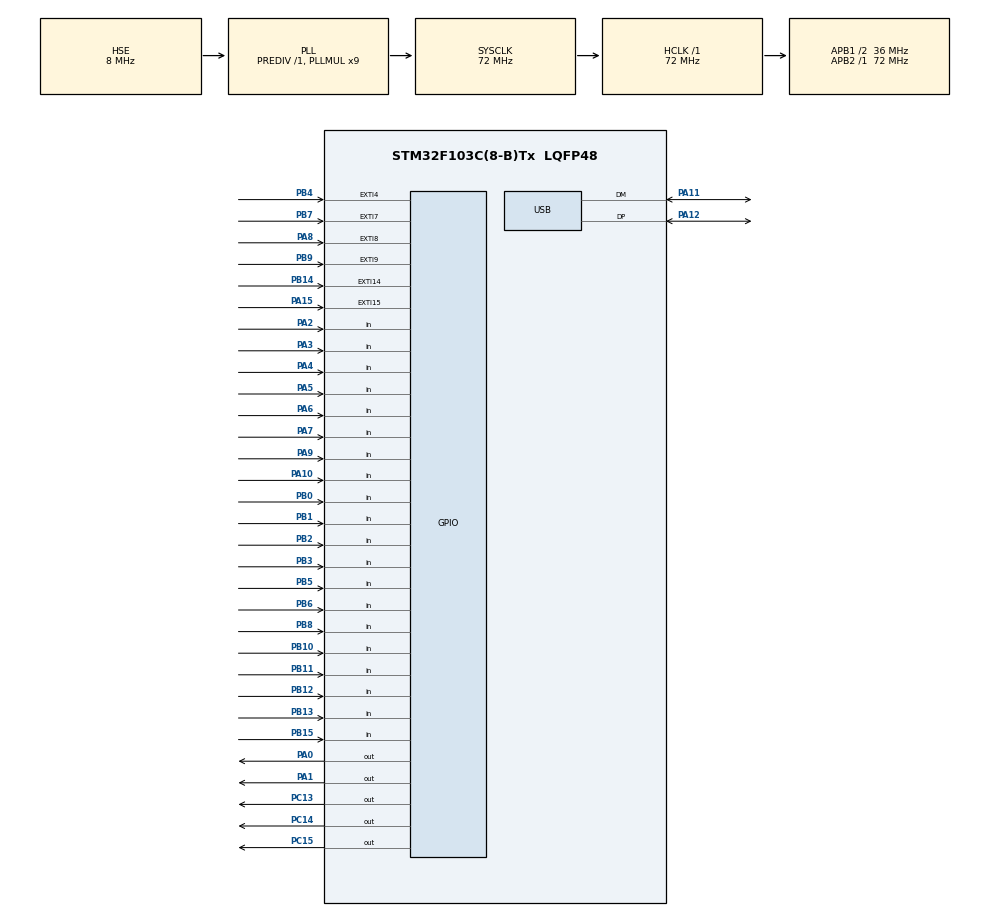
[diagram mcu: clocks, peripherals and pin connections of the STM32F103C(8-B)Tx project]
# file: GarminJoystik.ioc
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Mcu.Family=STM32F1
Mcu.Name=STM32F103C(8-B)Tx
Mcu.Package=LQFP48
NVIC.EXTI15_10_IRQn=true\:0\:0\:false\:false\:true\:true
NVIC.EXTI9_5_IRQn=true\:0\:0\:false\:false\:true\:true
NVIC.PriorityGroup=NVIC_PRIORITYGROUP_4
NVIC.USB_LP_CAN1_RX0_IRQn=true\:0\:0\:false\:false\:true\:true
PA0-WKUP.PinState=GPIO_PIN_SET
PA0-WKUP.Signal=GPIO_Output
PA1.PinState=GPIO_PIN_SET
PA1.Signal=GPIO_Output
PA10.GPIO_Mode=GPIO_MODE_INPUT
PA10.GPIO_PuPd=GPIO_PULLUP
PA10.Signal=GPIO_Input
PA11.Mode=Device
PA11.Signal=USB_DM
PA12.Mode=Device
PA12.Signal=USB_DP
PA13.Signal=SYS_JTMS-SWDIO
PA14.Signal=SYS_JTCK-SWCLK
PA15.GPIO_ModeDefaultEXTI=GPIO_MODE_IT_FALLING
PA15.GPIO_PuPd=GPIO_PULLUP
PA15.Signal=GPXTI15
PA2.GPIO_Mode=GPIO_MODE_INPUT
PA2.GPIO_PuPd=GPIO_PULLDOWN
PA2.Signal=GPIO_Input
PA3.GPIO_Mode=GPIO_MODE_INPUT
PA3.GPIO_PuPd=GPIO_PULLDOWN
PA3.Signal=GPIO_Input
PA4.GPIO_Mode=GPIO_MODE_INPUT
PA4.GPIO_PuPd=GPIO_PULLDOWN
PA4.Signal=GPIO_Input
PA5.GPIO_Mode=GPIO_MODE_INPUT
PA5.GPIO_PuPd=GPIO_PULLDOWN
PA5.Signal=GPIO_Input
PA6.GPIO_Mode=GPIO_MODE_INPUT
PA6.GPIO_PuPd=GPIO_PULLDOWN
PA6.Signal=GPIO_Input
PA7.GPIO_Mode=GPIO_MODE_INPUT
PA7.GPIO_PuPd=GPIO_PULLDOWN
PA7.Signal=GPIO_Input
PA8.GPIO_ModeDefaultEXTI=GPIO_MODE_IT_FALLING
PA8.GPIO_PuPd=GPIO_PULLUP
PA8.Signal=GPXTI8
PA9.GPIO_Mode=GPIO_MODE_INPUT
PA9.GPIO_PuPd=GPIO_PULLUP
PA9.Signal=GPIO_Input
PB0.GPIO_Mode=GPIO_MODE_INPUT
PB0.GPIO_PuPd=GPIO_PULLDOWN
PB0.Signal=GPIO_Input
PB1.GPIO_Mode=GPIO_MODE_INPUT
PB1.GPIO_PuPd=GPIO_PULLDOWN
PB1.Signal=GPIO_Input
PB10.GPIO_Mode=GPIO_MODE_INPUT
PB10.GPIO_PuPd=GPIO_PULLDOWN
PB10.Signal=GPIO_Input
PB11.GPIO_Mode=GPIO_MODE_INPUT
PB11.GPIO_PuPd=GPIO_PULLDOWN
PB11.Signal=GPIO_Input
PB12.GPIO_Mode=GPIO_MODE_INPUT
PB12.GPIO_PuPd=GPIO_PULLUP
PB12.Signal=GPIO_Input
PB13.GPIO_Mode=GPIO_MODE_INPUT
PB13.GPIO_PuPd=GPIO_PULLUP
PB13.Signal=GPIO_Input
PB14.GPIO_ModeDefaultEXTI=GPIO_MODE_IT_FALLING
PB14.GPIO_PuPd=GPIO_PULLUP
PB14.Signal=GPXTI14
PB15.GPIO_Mode=GPIO_MODE_INPUT
PB15.GPIO_PuPd=GPIO_PULLUP
PB15.Signal=GPIO_Input
PB2.GPIO_Mode=GPIO_MODE_INPUT
PB2.GPIO_PuPd=GPIO_PULLDOWN
PB2.Signal=GPIO_Input
PB3.GPIO_Mode=GPIO_MODE_INPUT
PB3.GPIO_PuPd=GPIO_PULLUP
PB3.Signal=GPIO_Input
PB4.GPIO_ModeDefaultEXTI=GPIO_MODE_IT_FALLING
PB4.GPIO_PuPd=GPIO_PULLUP
PB4.Signal=GPXTI4
PB5.GPIO_Mode=GPIO_MODE_INPUT
PB5.GPIO_PuPd=GPIO_PULLUP
PB5.Signal=GPIO_Input
PB6.GPIO_Mode=GPIO_MODE_INPUT
PB6.GPIO_PuPd=GPIO_PULLUP
PB6.Signal=GPIO_Input
PB7.GPIO_ModeDefaultEXTI=GPIO_MODE_IT_FALLING
PB7.GPIO_PuPd=GPIO_PULLUP
PB7.Signal=GPXTI7
PB8.GPIO_Mode=GPIO_MODE_INPUT
PB8.GPIO_PuPd=GPIO_PULLUP
PB8.Signal=GPIO_Input
PB9.GPIO_ModeDefaultEXTI=GPIO_MODE_IT_FALLING
PB9.GPIO_PuPd=GPIO_PULLUP
PB9.Signal=GPXTI9
PC13-TAMPER-RTC.PinState=GPIO_PIN_SET
PC13-TAMPER-RTC.Signal=GPIO_Output
PC14-OSC32_IN.PinState=GPIO_PIN_SET
PC14-OSC32_IN.Signal=GPIO_Output
PC15-OSC32_OUT.PinState=GPIO_PIN_SET
PC15-OSC32_OUT.Signal=GPIO_Output
PD0-OSC_IN.Mode=HSE-External-Oscillator
PD0-OSC_IN.Signal=RCC_OSC_IN
PD1-OSC_OUT.Mode=HSE-External-Oscillator
PD1-OSC_OUT.Signal=RCC_OSC_OUT
ProjectManager.HeapSize=0x200
ProjectManager.StackSize=0x400
ProjectManager.TargetToolchain=SW4STM32
RCC.AHBFreq_Value=72000000
RCC.APB1CLKDivider=RCC_HCLK_DIV2
RCC.APB1Freq_Value=36000000
RCC.APB1TimFreq_Value=72000000
RCC.APB2Freq_Value=72000000
RCC.APB2TimFreq_Value=72000000
RCC.HCLKFreq_Value=72000000
RCC.PLLMUL=RCC_PLL_MUL9
RCC.SYSCLKFreq_VALUE=72000000
RCC.SYSCLKSource=RCC_SYSCLKSOURCE_PLLCLK
RCC.USBFreq_Value=48000000
RCC.USBPrescaler=RCC_USBCLKSOURCE_PLL_DIV1_5
USB_DEVICE.CLASS_NAME_FS=CUSTOMHID
USB_DEVICE.MANUFACTURER_STRING=Iezious
USB_DEVICE.PID_CUSTOMHID_FS=53223 
USB_DEVICE.PRODUCT_STRING_CUSTOMHID_FS=GNS530 Joystick
USB_DEVICE.SERIALNUMBER_STRING_CUSTOMHID_FS=00000000011B
USB_DEVICE.VirtualMode=CustomHid
USB_DEVICE.VirtualModeFS=Custom_Hid_FS
VP_SYS_VS_ND.Mode=No_Debug
VP_USB_DEVICE_VS_USB_DEVICE_CUSTOM_HID_FS.Mode=CUSTOM_HID_FS
board=custom

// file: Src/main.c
/**
  ******************************************************************************
  * @file           : main.c
  * @brief          : Main program body
  ******************************************************************************
  * This notice applies to any and all portions of this file
  * that are not between comment pairs USER CODE BEGIN and
  * USER CODE END. Other portions of this file, whether
  * inserted by the user or by software development tools
  * are owned by their respective copyright owners.
  *
  * Copyright (c) 2018 STMicroelectronics International N.V.
  * All rights reserved.
  *
  * Redistribution and use in source and binary forms, with or without
  * modification, are permitted, provided that the following conditions are met:
  *
  * 1. Redistribution of source code must retain the above copyright notice,
  *    this list of conditions and the following disclaimer.
  * 2. Redistributions in binary form must reproduce the above copyright notice,
  *    this list of conditions and the following disclaimer in the documentation
  *    and/or other materials provided with the distribution.
  * 3. Neither the name of STMicroelectronics nor the names of other
  *    contributors to this software may be used to endorse or promote products
  *    derived from this software without specific written permission.
  * 4. This software, including modifications and/or derivative works of this
  *    software, must execute solely and exclusively on microcontroller or
  *    microprocessor devices manufactured by or for STMicroelectronics.
  * 5. Redistribution and use of this software other than as permitted under
  *    this license is void and will automatically terminate your rights under
  *    this license.
  *
  * THIS SOFTWARE IS PROVIDED BY STMICROELECTRONICS AND CONTRIBUTORS "AS IS"
  * AND ANY EXPRESS, IMPLIED OR STATUTORY WARRANTIES, INCLUDING, BUT NOT
  * LIMITED TO, THE IMPLIED WARRANTIES OF MERCHANTABILITY, FITNESS FOR A
  * PARTICULAR PURPOSE AND NON-INFRINGEMENT OF THIRD PARTY INTELLECTUAL PROPERTY
  * RIGHTS ARE DISCLAIMED TO THE FULLEST EXTENT PERMITTED BY LAW. IN NO EVENT
  * SHALL STMICROELECTRONICS OR CONTRIBUTORS BE LIABLE FOR ANY DIRECT, INDIRECT,
  * INCIDENTAL, SPECIAL, EXEMPLARY, OR CONSEQUENTIAL DAMAGES (INCLUDING, BUT NOT
  * LIMITED TO, PROCUREMENT OF SUBSTITUTE GOODS OR SERVICES; LOSS OF USE, DATA,
  * OR PROFITS; OR BUSINESS INTERRUPTION) HOWEVER CAUSED AND ON ANY THEORY OF
  * LIABILITY, WHETHER IN CONTRACT, STRICT LIABILITY, OR TORT (INCLUDING
  * NEGLIGENCE OR OTHERWISE) ARISING IN ANY WAY OUT OF THE USE OF THIS SOFTWARE,
  * EVEN IF ADVISED OF THE POSSIBILITY OF SUCH DAMAGE.
  *
  ******************************************************************************
  */
#include "main.h"
#include "stm32f1xx_hal.h"
#include "usb_device.h"
#include "joylogic.h"

/* USER CODE BEGIN PV */
/* Private variables ---------------------------------------------------------*/

/* USER CODE END PV */

void SystemClock_Config(void);
static void MX_GPIO_Init(void);

/* USER CODE BEGIN PFP */
/* Private function prototypes -----------------------------------------------*/

/* USER CODE END PFP */

int main(void)
{

  /* MCU Configuration----------------------------------------------------------*/

  /* Reset of all peripherals, Initializes the Flash interface and the Systick. */
  HAL_Init();

  /* Configure the system clock */
  SystemClock_Config();

  /* Initialize all configured peripherals */
  MX_GPIO_Init();
  MX_USB_DEVICE_Init();
  /* USER CODE BEGIN 2 */

  HAL_Delay(1000);
  /* USER CODE END 2 */

  /* Infinite loop */
  while (1)
  {

  /* USER CODE BEGIN 3 */

    JoystickCycle();

  }
  /* USER CODE END 3 */

}

void SystemClock_Config(void)
{

  RCC_OscInitTypeDef RCC_OscInitStruct;
  RCC_ClkInitTypeDef RCC_ClkInitStruct;
  RCC_PeriphCLKInitTypeDef PeriphClkInit;

    /**Initializes the CPU, AHB and APB busses clocks
    */
  RCC_OscInitStruct.OscillatorType = RCC_OSCILLATORTYPE_HSE;
  RCC_OscInitStruct.HSEState = RCC_HSE_ON;
  RCC_OscInitStruct.HSEPredivValue = RCC_HSE_PREDIV_DIV1;
  RCC_OscInitStruct.HSIState = RCC_HSI_ON;
  RCC_OscInitStruct.PLL.PLLState = RCC_PLL_ON;
  RCC_OscInitStruct.PLL.PLLSource = RCC_PLLSOURCE_HSE;
  RCC_OscInitStruct.PLL.PLLMUL = RCC_PLL_MUL9;
  if (HAL_RCC_OscConfig(&RCC_OscInitStruct) != HAL_OK)
  {
    _Error_Handler(__FILE__, __LINE__);
  }

    /**Initializes the CPU, AHB and APB busses clocks
    */
  RCC_ClkInitStruct.ClockType = RCC_CLOCKTYPE_HCLK|RCC_CLOCKTYPE_SYSCLK
                              |RCC_CLOCKTYPE_PCLK1|RCC_CLOCKTYPE_PCLK2;
  RCC_ClkInitStruct.SYSCLKSource = RCC_SYSCLKSOURCE_PLLCLK;
  RCC_ClkInitStruct.AHBCLKDivider = RCC_SYSCLK_DIV1;
  RCC_ClkInitStruct.APB1CLKDivider = RCC_HCLK_DIV2;
  RCC_ClkInitStruct.APB2CLKDivider = RCC_HCLK_DIV1;

  if (HAL_RCC_ClockConfig(&RCC_ClkInitStruct, FLASH_LATENCY_2) != HAL_OK)
  {
    _Error_Handler(__FILE__, __LINE__);
  }

  PeriphClkInit.PeriphClockSelection = RCC_PERIPHCLK_USB;
  PeriphClkInit.UsbClockSelection = RCC_USBCLKSOURCE_PLL_DIV1_5;
  if (HAL_RCCEx_PeriphCLKConfig(&PeriphClkInit) != HAL_OK)
  {
    _Error_Handler(__FILE__, __LINE__);
  }

    /**Configure the Systick interrupt time
    */
  HAL_SYSTICK_Config(HAL_RCC_GetHCLKFreq()/1000);

    /**Configure the Systick
    */
  HAL_SYSTICK_CLKSourceConfig(SYSTICK_CLKSOURCE_HCLK);

  /* SysTick_IRQn interrupt configuration */
  HAL_NVIC_SetPriority(SysTick_IRQn, 0, 0);
}

/** Configure pins as
        * Analog
        * Input
        * Output
        * EVENT_OUT
        * EXTI
*/
static void MX_GPIO_Init(void)
{

  GPIO_InitTypeDef GPIO_InitStruct;

  /* GPIO Ports Clock Enable */
  __HAL_RCC_GPIOC_CLK_ENABLE();
  __HAL_RCC_GPIOD_CLK_ENABLE();
  __HAL_RCC_GPIOA_CLK_ENABLE();
  __HAL_RCC_GPIOB_CLK_ENABLE();

  /*Configure GPIO pin Output Level */
  HAL_GPIO_WritePin(GPIOC, GPIO_PIN_13|GPIO_PIN_14|GPIO_PIN_15, GPIO_PIN_SET);

  /*Configure GPIO pin Output Level */
  HAL_GPIO_WritePin(GPIOA, GPIO_PIN_0|GPIO_PIN_1, GPIO_PIN_SET);

  /*Configure GPIO pins : PC13 PC14 PC15 */
  GPIO_InitStruct.Pin = GPIO_PIN_13|GPIO_PIN_14|GPIO_PIN_15;
  GPIO_InitStruct.Mode = GPIO_MODE_OUTPUT_PP;
  GPIO_InitStruct.Pull = GPIO_NOPULL;
  GPIO_InitStruct.Speed = GPIO_SPEED_FREQ_LOW;
  HAL_GPIO_Init(GPIOC, &GPIO_InitStruct);

  /*Configure GPIO pins : PA0 PA1 */
  GPIO_InitStruct.Pin = GPIO_PIN_0|GPIO_PIN_1;
  GPIO_InitStruct.Mode = GPIO_MODE_OUTPUT_PP;
  GPIO_InitStruct.Pull = GPIO_NOPULL;
  GPIO_InitStruct.Speed = GPIO_SPEED_FREQ_LOW;
  HAL_GPIO_Init(GPIOA, &GPIO_InitStruct);

  /*Configure GPIO pins : PA2 PA3 PA4 PA5
                           PA6 PA7 */
  GPIO_InitStruct.Pin = GPIO_PIN_2|GPIO_PIN_3|GPIO_PIN_4|GPIO_PIN_5
                          |GPIO_PIN_6|GPIO_PIN_7;
  GPIO_InitStruct.Mode = GPIO_MODE_INPUT;
  GPIO_InitStruct.Pull = GPIO_PULLDOWN;
  HAL_GPIO_Init(GPIOA, &GPIO_InitStruct);

  /*Configure GPIO pins : PB0 PB1 PB2 PB10
                           PB11 */
  GPIO_InitStruct.Pin = GPIO_PIN_0|GPIO_PIN_1|GPIO_PIN_2|GPIO_PIN_10
                          |GPIO_PIN_11;
  GPIO_InitStruct.Mode = GPIO_MODE_INPUT;
  GPIO_InitStruct.Pull = GPIO_PULLDOWN;
  HAL_GPIO_Init(GPIOB, &GPIO_InitStruct);

  /*Configure GPIO pins : PB12 PB13 PB15 PB3
                           PB5 PB6 PB8 */
  GPIO_InitStruct.Pin = GPIO_PIN_12|GPIO_PIN_13|GPIO_PIN_15|GPIO_PIN_3
                          |GPIO_PIN_5|GPIO_PIN_6|GPIO_PIN_8;
  GPIO_InitStruct.Mode = GPIO_MODE_INPUT;
  GPIO_InitStruct.Pull = GPIO_PULLUP;
  HAL_GPIO_Init(GPIOB, &GPIO_InitStruct);

  /*Configure GPIO pins : PB14 PB4 PB7 PB9 */
  GPIO_InitStruct.Pin = GPIO_PIN_14|GPIO_PIN_4|GPIO_PIN_7|GPIO_PIN_9;
  GPIO_InitStruct.Mode = GPIO_MODE_IT_FALLING;
  GPIO_InitStruct.Pull = GPIO_PULLUP;
  HAL_GPIO_Init(GPIOB, &GPIO_InitStruct);

  /*Configure GPIO pins : PA8 PA15 */
  GPIO_InitStruct.Pin = GPIO_PIN_8|GPIO_PIN_15;
  GPIO_InitStruct.Mode = GPIO_MODE_IT_FALLING;
  GPIO_InitStruct.Pull = GPIO_PULLUP;
  HAL_GPIO_Init(GPIOA, &GPIO_InitStruct);

  /*Configure GPIO pins : PA9 PA10 */
  GPIO_InitStruct.Pin = GPIO_PIN_9|GPIO_PIN_10;
  GPIO_InitStruct.Mode = GPIO_MODE_INPUT;
  GPIO_InitStruct.Pull = GPIO_PULLUP;
  HAL_GPIO_Init(GPIOA, &GPIO_InitStruct);

  /* EXTI interrupt init*/
  HAL_NVIC_SetPriority(EXTI9_5_IRQn, 0, 0);
  HAL_NVIC_EnableIRQ(EXTI9_5_IRQn);

  HAL_NVIC_SetPriority(EXTI15_10_IRQn, 0, 0);
  HAL_NVIC_EnableIRQ(EXTI15_10_IRQn);

}

void _Error_Handler(char *file, int line)
{
  while(1)
  {
  }
}

/************************ (C) COPYRIGHT STMicroelectronics *****END OF FILE****/
